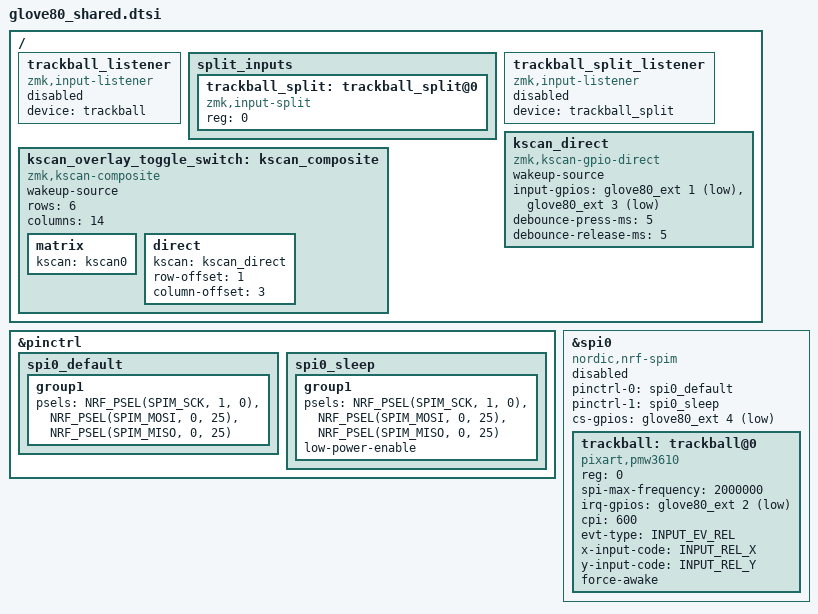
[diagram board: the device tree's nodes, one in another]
#define SPI_PSELS(sck_port, sck_pin, sdio_port, sdio_pin) \
    <NRF_PSEL(SPIM_SCK, sck_port, sck_pin)>, \
    <NRF_PSEL(SPIM_MOSI, sdio_port, sdio_pin)>, \
    <NRF_PSEL(SPIM_MISO, sdio_port, sdio_pin)>

&pinctrl {
    spi0_default: spi0_default {
        group1 {
            psels = <NRF_PSEL(SPIM_SCK, 1, 0)>,
                <NRF_PSEL(SPIM_MOSI, 0, 25)>,
                <NRF_PSEL(SPIM_MISO, 0, 25)>;
        }
    };

    spi0_sleep: spi0_sleep {
        group1 {
            psels = <NRF_PSEL(SPIM_SCK, 1, 0)>,
                <NRF_PSEL(SPIM_MOSI, 0, 25)>,
                <NRF_PSEL(SPIM_MISO, 0, 25)>;
            low-power-enable;
        }
    };
};

#include <zephyr/dt-bindings/input/input-event-codes.h>

&spi0 {
    status = "disabled";
    compatible = "nordic,nrf-spim";
    pinctrl-0 = <&spi0_default>;
    pinctrl-1 = <&spi0_sleep>;
    pinctrl-names = "default", "sleep";
    cs-gpios = <&glove80_ext 4 GPIO_ACTIVE_LOW>; /* nCS = EXT4 = P0.25 */
    /*cs-gpios = <&gpio0 25 GPIO_ACTIVE_LOW>;*/

    trackball: trackball@0 {
        status = "okay";
        compatible = "pixart,pmw3610";
        reg = <0>;
        spi-max-frequency = <2000000>;
        irq-gpios = <&glove80_ext 2 (GPIO_ACTIVE_LOW | GPIO_PULL_UP)>; /* Mot = EXT2 = P0.24 */
        /*irq-gpios = <&gpio0 24 (GPIO_ACTIVE_LOW | GPIO_PULL_UP)>;*/
        cpi = <600>;
        evt-type = <INPUT_EV_REL>;
        x-input-code = <INPUT_REL_X>;
        y-input-code = <INPUT_REL_Y>;

        force-awake;
        /* keep the sensor awake while ZMK activity state is ACTIVE,
           fallback to normal downshift mode after ZMK goes into IDLE / SLEEP mode.
           thus, the sensor would be a `wakeup-source` */
    };
};

#include <dt-bindings/zmk/keys.h>

/ {
    // regular listener if trackball is used on split central
    trackball_listener: trackball_listener {
        compatible = "zmk,input-listener";
        status = "disabled";
        device = <&trackball>;
    };

    split_inputs {
        #address-cells = <1>;
        #size-cells = <0>;

        trackball_split: trackball_split@0 {
            compatible = "zmk,input-split";
            reg = <0>;
        };
    };

    // split listener if trackball is used on split peripheral over BLE
    trackball_split_listener: trackball_split_listener {
        compatible = "zmk,input-listener";
        status = "disabled";
        device = <&trackball_split>;
    };

    // https://zmk.dev/docs/config/kscan#direct-gpio-driver
    // CONFIG_ZMK_KSCAN_DIRECT_POLLING=n // we don't want active pulling to save battery
    // todo: check if it's enabled by default for glove80
    // toggle-mode not needed, because we use a spring switch with momentary signals only

    // Direct GPIO kscan for the toggle switche
    kscan_direct: kscan_direct {
        compatible = "zmk,kscan-gpio-direct";
        wakeup-source;
        
        input-gpios = <&glove80_ext 1 (GPIO_ACTIVE_LOW | GPIO_PULL_UP)>,
                      <&glove80_ext 3 (GPIO_ACTIVE_LOW | GPIO_PULL_UP)>;
        
        debounce-press-ms = <5>;
        debounce-release-ms = <5>;
    };

    // Composite kscan that combines the original matrix with direct GPIO
    kscan_overlay_toggle_switch: kscan_composite {
        compatible = "zmk,kscan-composite";
        wakeup-source;
        
        // The Glove80 has a 6x14 matrix (6 rows, 14 columns)
        rows = <6>;
        columns = <14>;
        
        // Include the original Glove80 matrix kscan from https://github.com/moergo-sc/zmk/blob/main/app/boards/arm/glove80/glove80.dtsi
        matrix {
            kscan = <&kscan0>;
        };
        
        // Include the direct GPIO switch
        // Position them at RC(1,1) and RC(1,2) to overlay with N1 and N2
        direct {
            kscan = <&kscan_direct>;
            row-offset = <1>;     // Row 1
            column-offset = <3>;  // Starting at column 1
        };
    };
};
